AUTOSAR XML (schema 4-2-2)
package /UAES/ASW
  swc implementation Implementation: programming-language=C, sw-version=1.32.1, used-code-generator=Embedded Coder 7.1 (R2018b) 24-May-2018, vendor-id=0, behavior=InternalBehavior
    code-descriptors:
      code Code
        artifact-descriptors:
          short-label=IntLamp_ComCnvRx_c, category=SWSRC
          short-label=IntLamp_ComCnvRx_h, category=SWHDR
          short-label=rtwtypes_h, category=SWHDR
    resource consumption RsrcCons_IntLamp_ComCnvRx
package /UAES/ASW/SwComponentTypes
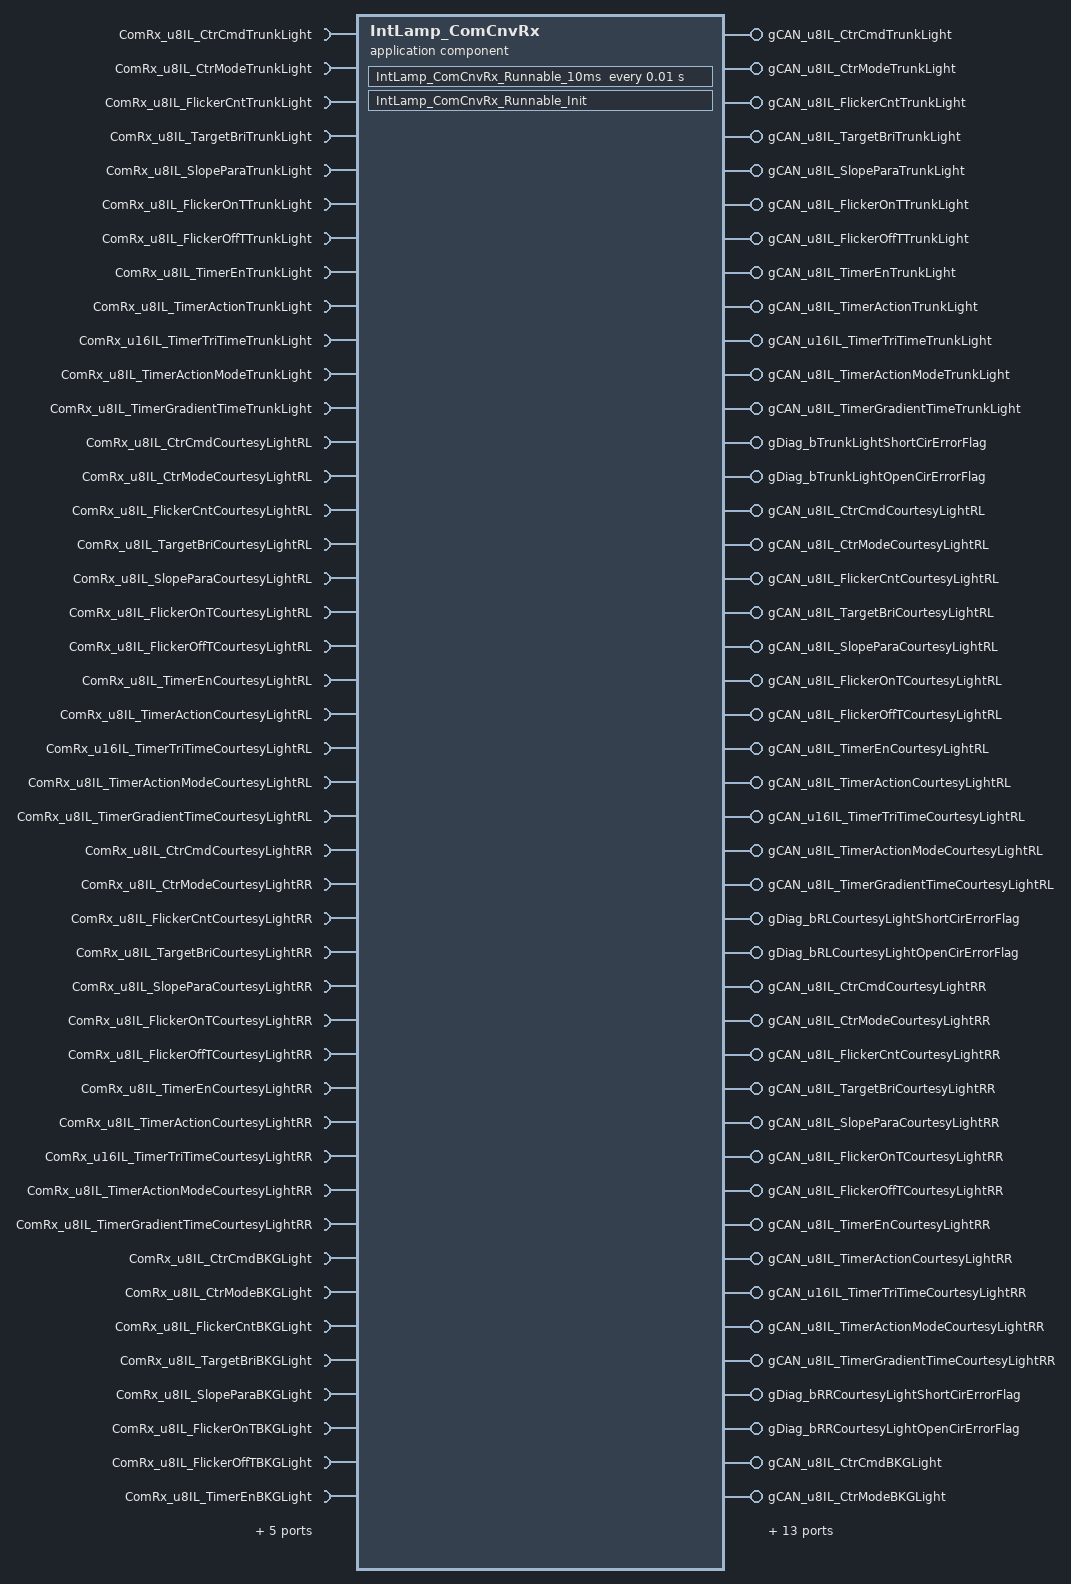
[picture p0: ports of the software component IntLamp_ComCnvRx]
  application sw component type IntLamp_ComCnvRx
    49 x require port:
      ComRx_u8IL_CtrCmdTrunkLight: nonqueued-receiver-com-spec{data-element=ComRx_u8IL_CtrCmdTrunkLight/Val, init-value=0}, required-interface=ComRx_u8IL_CtrCmdTrunkLight
      ComRx_u8IL_CtrModeTrunkLight: nonqueued-receiver-com-spec{data-element=ComRx_u8IL_CtrModeTrunkLight/Val, init-value=0}, required-interface=ComRx_u8IL_CtrModeTrunkLight
      ComRx_u8IL_FlickerCntTrunkLight: nonqueued-receiver-com-spec{data-element=ComRx_u8IL_FlickerCntTrunkLight/Val, init-value=0}, required-interface=ComRx_u8IL_FlickerCntTrunkLight
      ComRx_u8IL_TargetBriTrunkLight: nonqueued-receiver-com-spec{data-element=ComRx_u8IL_TargetBriTrunkLight/Val, init-value=0}, required-interface=ComRx_u8IL_TargetBriTrunkLight
      ComRx_u8IL_SlopeParaTrunkLight: nonqueued-receiver-com-spec{data-element=ComRx_u8IL_SlopeParaTrunkLight/Val, init-value=0}, required-interface=ComRx_u8IL_SlopeParaTrunkLight
      ComRx_u8IL_FlickerOnTTrunkLight: nonqueued-receiver-com-spec{data-element=ComRx_u8IL_FlickerOnTTrunkLight/Val, init-value=0}, required-interface=ComRx_u8IL_FlickerOnTTrunkLight
      ComRx_u8IL_FlickerOffTTrunkLight: nonqueued-receiver-com-spec{data-element=ComRx_u8IL_FlickerOffTTrunkLight/Val, init-value=0}, required-interface=ComRx_u8IL_FlickerOffTTrunkLight
      ComRx_u8IL_TimerEnTrunkLight: nonqueued-receiver-com-spec{data-element=ComRx_u8IL_TimerEnTrunkLight/Val, init-value=0}, required-interface=ComRx_u8IL_TimerEnTrunkLight
      ComRx_u8IL_TimerActionTrunkLight: nonqueued-receiver-com-spec{data-element=ComRx_u8IL_TimerActionTrunkLight/Val, init-value=0}, required-interface=ComRx_u8IL_TimerActionTrunkLight
      ComRx_u16IL_TimerTriTimeTrunkLight: nonqueued-receiver-com-spec{data-element=ComRx_u16IL_TimerTriTimeTrunkLight/Val, init-value=0}, required-interface=ComRx_u16IL_TimerTriTimeTrunkLight
      ComRx_u8IL_TimerActionModeTrunkLight: nonqueued-receiver-com-spec{data-element=ComRx_u8IL_TimerActionModeTrunkLight/Val, init-value=0}, required-interface=ComRx_u8IL_TimerActionModeTrunkLight
      ComRx_u8IL_TimerGradientTimeTrunkLight: nonqueued-receiver-com-spec{data-element=ComRx_u8IL_TimerGradientTimeTrunkLight/Val, init-value=0}, required-interface=ComRx_u8IL_TimerGradientTimeTrunkLight
      ComRx_u8IL_CtrCmdCourtesyLightRL: nonqueued-receiver-com-spec{data-element=ComRx_u8IL_CtrCmdCourtesyLightRL/Val, init-value=0}, required-interface=ComRx_u8IL_CtrCmdCourtesyLightRL
      ComRx_u8IL_CtrModeCourtesyLightRL: nonqueued-receiver-com-spec{data-element=ComRx_u8IL_CtrModeCourtesyLightRL/Val, init-value=0}, required-interface=ComRx_u8IL_CtrModeCourtesyLightRL
      ComRx_u8IL_FlickerCntCourtesyLightRL: nonqueued-receiver-com-spec{data-element=ComRx_u8IL_FlickerCntCourtesyLightRL/Val, init-value=0}, required-interface=ComRx_u8IL_FlickerCntCourtesyLightRL
      ComRx_u8IL_TargetBriCourtesyLightRL: nonqueued-receiver-com-spec{data-element=ComRx_u8IL_TargetBriCourtesyLightRL/Val, init-value=0}, required-interface=ComRx_u8IL_TargetBriCourtesyLightRL
      ComRx_u8IL_SlopeParaCourtesyLightRL: nonqueued-receiver-com-spec{data-element=ComRx_u8IL_SlopeParaCourtesyLightRL/Val, init-value=0}, required-interface=ComRx_u8IL_SlopeParaCourtesyLightRL
      ComRx_u8IL_FlickerOnTCourtesyLightRL: nonqueued-receiver-com-spec{data-element=ComRx_u8IL_FlickerOnTCourtesyLightRL/Val, init-value=0}, required-interface=ComRx_u8IL_FlickerOnTCourtesyLightRL
      ComRx_u8IL_FlickerOffTCourtesyLightRL: nonqueued-receiver-com-spec{data-element=ComRx_u8IL_FlickerOffTCourtesyLightRL/Val, init-value=0}, required-interface=ComRx_u8IL_FlickerOffTCourtesyLightRL
      ComRx_u8IL_TimerEnCourtesyLightRL: nonqueued-receiver-com-spec{data-element=ComRx_u8IL_TimerEnCourtesyLightRL/Val, init-value=0}, required-interface=ComRx_u8IL_TimerEnCourtesyLightRL
      ComRx_u8IL_TimerActionCourtesyLightRL: nonqueued-receiver-com-spec{data-element=ComRx_u8IL_TimerActionCourtesyLightRL/Val, init-value=0}, required-interface=ComRx_u8IL_TimerActionCourtesyLightRL
      ComRx_u16IL_TimerTriTimeCourtesyLightRL: nonqueued-receiver-com-spec{data-element=ComRx_u16IL_TimerTriTimeCourtesyLightRL/Val, init-value=0}, required-interface=ComRx_u16IL_TimerTriTimeCourtesyLightRL
      ComRx_u8IL_TimerActionModeCourtesyLightRL: nonqueued-receiver-com-spec{data-element=ComRx_u8IL_TimerActionModeCourtesyLightRL/Val, init-value=0}, required-interface=ComRx_u8IL_TimerActionModeCourtesyLightRL
      ComRx_u8IL_TimerGradientTimeCourtesyLightRL: nonqueued-receiver-com-spec{data-element=ComRx_u8IL_TimerGradientTimeCourtesyLightRL/Val, init-value=0}, required-interface=ComRx_u8IL_TimerGradientTimeCourtesyLightRL
      ComRx_u8IL_CtrCmdCourtesyLightRR: nonqueued-receiver-com-spec{data-element=ComRx_u8IL_CtrCmdCourtesyLightRR/Val, init-value=0}, required-interface=ComRx_u8IL_CtrCmdCourtesyLightRR
      ComRx_u8IL_CtrModeCourtesyLightRR: nonqueued-receiver-com-spec{data-element=ComRx_u8IL_CtrModeCourtesyLightRR/Val, init-value=0}, required-interface=ComRx_u8IL_CtrModeCourtesyLightRR
      ComRx_u8IL_FlickerCntCourtesyLightRR: nonqueued-receiver-com-spec{data-element=ComRx_u8IL_FlickerCntCourtesyLightRR/Val, init-value=0}, required-interface=ComRx_u8IL_FlickerCntCourtesyLightRR
      ComRx_u8IL_TargetBriCourtesyLightRR: nonqueued-receiver-com-spec{data-element=ComRx_u8IL_TargetBriCourtesyLightRR/Val, init-value=0}, required-interface=ComRx_u8IL_TargetBriCourtesyLightRR
      ComRx_u8IL_SlopeParaCourtesyLightRR: nonqueued-receiver-com-spec{data-element=ComRx_u8IL_SlopeParaCourtesyLightRR/Val, init-value=0}, required-interface=ComRx_u8IL_SlopeParaCourtesyLightRR
      ComRx_u8IL_FlickerOnTCourtesyLightRR: nonqueued-receiver-com-spec{data-element=ComRx_u8IL_FlickerOnTCourtesyLightRR/Val, init-value=0}, required-interface=ComRx_u8IL_FlickerOnTCourtesyLightRR
      ComRx_u8IL_FlickerOffTCourtesyLightRR: nonqueued-receiver-com-spec{data-element=ComRx_u8IL_FlickerOffTCourtesyLightRR/Val, init-value=0}, required-interface=ComRx_u8IL_FlickerOffTCourtesyLightRR
      ComRx_u8IL_TimerEnCourtesyLightRR: nonqueued-receiver-com-spec{data-element=ComRx_u8IL_TimerEnCourtesyLightRR/Val, init-value=0}, required-interface=ComRx_u8IL_TimerEnCourtesyLightRR
      ComRx_u8IL_TimerActionCourtesyLightRR: nonqueued-receiver-com-spec{data-element=ComRx_u8IL_TimerActionCourtesyLightRR/Val, init-value=0}, required-interface=ComRx_u8IL_TimerActionCourtesyLightRR
      ComRx_u16IL_TimerTriTimeCourtesyLightRR: nonqueued-receiver-com-spec{data-element=ComRx_u16IL_TimerTriTimeCourtesyLightRR/Val, init-value=0}, required-interface=ComRx_u16IL_TimerTriTimeCourtesyLightRR
      ComRx_u8IL_TimerActionModeCourtesyLightRR: nonqueued-receiver-com-spec{data-element=ComRx_u8IL_TimerActionModeCourtesyLightRR/Val, init-value=0}, required-interface=ComRx_u8IL_TimerActionModeCourtesyLightRR
      ComRx_u8IL_TimerGradientTimeCourtesyLightRR: nonqueued-receiver-com-spec{data-element=ComRx_u8IL_TimerGradientTimeCourtesyLightRR/Val, init-value=0}, required-interface=ComRx_u8IL_TimerGradientTimeCourtesyLightRR
      ComRx_u8IL_CtrCmdBKGLight: nonqueued-receiver-com-spec{data-element=ComRx_u8IL_CtrCmdBKGLight/Val, init-value=0}, required-interface=ComRx_u8IL_CtrCmdBKGLight
      ComRx_u8IL_CtrModeBKGLight: nonqueued-receiver-com-spec{data-element=ComRx_u8IL_CtrModeBKGLight/Val, init-value=0}, required-interface=ComRx_u8IL_CtrModeBKGLight
      ComRx_u8IL_FlickerCntBKGLight: nonqueued-receiver-com-spec{data-element=ComRx_u8IL_FlickerCntBKGLight/Val, init-value=0}, required-interface=ComRx_u8IL_FlickerCntBKGLight
      ComRx_u8IL_TargetBriBKGLight: nonqueued-receiver-com-spec{data-element=ComRx_u8IL_TargetBriBKGLight/Val, init-value=0}, required-interface=ComRx_u8IL_TargetBriBKGLight
      ComRx_u8IL_SlopeParaBKGLight: nonqueued-receiver-com-spec{data-element=ComRx_u8IL_SlopeParaBKGLight/Val, init-value=0}, required-interface=ComRx_u8IL_SlopeParaBKGLight
      ComRx_u8IL_FlickerOnTBKGLight: nonqueued-receiver-com-spec{data-element=ComRx_u8IL_FlickerOnTBKGLight/Val, init-value=0}, required-interface=ComRx_u8IL_FlickerOnTBKGLight
      ComRx_u8IL_FlickerOffTBKGLight: nonqueued-receiver-com-spec{data-element=ComRx_u8IL_FlickerOffTBKGLight/Val, init-value=0}, required-interface=ComRx_u8IL_FlickerOffTBKGLight
      ComRx_u8IL_TimerEnBKGLight: nonqueued-receiver-com-spec{data-element=ComRx_u8IL_TimerEnBKGLight/Val, init-value=0}, required-interface=ComRx_u8IL_TimerEnBKGLight
      ComRx_u8IL_TimerActionBKGLight: nonqueued-receiver-com-spec{data-element=ComRx_u8IL_TimerActionBKGLight/Val, init-value=0}, required-interface=ComRx_u8IL_TimerActionBKGLight
      ComRx_u16IL_TimerTriTimeBKGLight: nonqueued-receiver-com-spec{data-element=ComRx_u16IL_TimerTriTimeBKGLight/Val, init-value=0}, required-interface=ComRx_u16IL_TimerTriTimeBKGLight
      ComRx_u8IL_TimerActionModeBKGLight: nonqueued-receiver-com-spec{data-element=ComRx_u8IL_TimerActionModeBKGLight/Val, init-value=0}, required-interface=ComRx_u8IL_TimerActionModeBKGLight
      ComRx_u8IL_TimerGradientTimeBKGLight: nonqueued-receiver-com-spec{data-element=ComRx_u8IL_TimerGradientTimeBKGLight/Val, init-value=0}, required-interface=ComRx_u8IL_TimerGradientTimeBKGLight
      ComRx_bIL_CtrCmdTrunkLight_TiOut: nonqueued-receiver-com-spec{data-element=ComRx_bIL_CtrCmdTrunkLight_TiOut/Val, init-value=0}, required-interface=ComRx_bIL_CtrCmdTrunkLight_TiOut
    57 x provide port:
      gCAN_u8IL_CtrCmdTrunkLight: nonqueued-sender-com-spec{data-element=gCAN_u8IL_CtrCmdTrunkLight/Val, init-value=0}, provided-interface=gCAN_u8IL_CtrCmdTrunkLight
      gCAN_u8IL_CtrModeTrunkLight: nonqueued-sender-com-spec{data-element=gCAN_u8IL_CtrModeTrunkLight/Val, init-value=0}, provided-interface=gCAN_u8IL_CtrModeTrunkLight
      gCAN_u8IL_FlickerCntTrunkLight: nonqueued-sender-com-spec{data-element=gCAN_u8IL_FlickerCntTrunkLight/Val, init-value=0}, provided-interface=gCAN_u8IL_FlickerCntTrunkLight
      gCAN_u8IL_TargetBriTrunkLight: nonqueued-sender-com-spec{data-element=gCAN_u8IL_TargetBriTrunkLight/Val, init-value=0}, provided-interface=gCAN_u8IL_TargetBriTrunkLight
      gCAN_u8IL_SlopeParaTrunkLight: nonqueued-sender-com-spec{data-element=gCAN_u8IL_SlopeParaTrunkLight/Val, init-value=0}, provided-interface=gCAN_u8IL_SlopeParaTrunkLight
      gCAN_u8IL_FlickerOnTTrunkLight: nonqueued-sender-com-spec{data-element=gCAN_u8IL_FlickerOnTTrunkLight/Val, init-value=0}, provided-interface=gCAN_u8IL_FlickerOnTTrunkLight
      gCAN_u8IL_FlickerOffTTrunkLight: nonqueued-sender-com-spec{data-element=gCAN_u8IL_FlickerOffTTrunkLight/Val, init-value=0}, provided-interface=gCAN_u8IL_FlickerOffTTrunkLight
      gCAN_u8IL_TimerEnTrunkLight: nonqueued-sender-com-spec{data-element=gCAN_u8IL_TimerEnTrunkLight/Val, init-value=0}, provided-interface=gCAN_u8IL_TimerEnTrunkLight
      gCAN_u8IL_TimerActionTrunkLight: nonqueued-sender-com-spec{data-element=gCAN_u8IL_TimerActionTrunkLight/Val, init-value=0}, provided-interface=gCAN_u8IL_TimerActionTrunkLight
      gCAN_u16IL_TimerTriTimeTrunkLight: nonqueued-sender-com-spec{data-element=gCAN_u16IL_TimerTriTimeTrunkLight/Val, init-value=0}, provided-interface=gCAN_u16IL_TimerTriTimeTrunkLight
      gCAN_u8IL_TimerActionModeTrunkLight: nonqueued-sender-com-spec{data-element=gCAN_u8IL_TimerActionModeTrunkLight/Val, init-value=0}, provided-interface=gCAN_u8IL_TimerActionModeTrunkLight
      gCAN_u8IL_TimerGradientTimeTrunkLight: nonqueued-sender-com-spec{data-element=gCAN_u8IL_TimerGradientTimeTrunkLight/Val, init-value=0}, provided-interface=gCAN_u8IL_TimerGradientTimeTrunkLight
      gDiag_bTrunkLightShortCirErrorFlag: nonqueued-sender-com-spec{data-element=gDiag_bTrunkLightShortCirErrorFlag/Val, init-value=0}, provided-interface=gDiag_bTrunkLightShortCirErrorFlag
      gDiag_bTrunkLightOpenCirErrorFlag: nonqueued-sender-com-spec{data-element=gDiag_bTrunkLightOpenCirErrorFlag/Val, init-value=0}, provided-interface=gDiag_bTrunkLightOpenCirErrorFlag
      gCAN_u8IL_CtrCmdCourtesyLightRL: nonqueued-sender-com-spec{data-element=gCAN_u8IL_CtrCmdCourtesyLightRL/Val, init-value=0}, provided-interface=gCAN_u8IL_CtrCmdCourtesyLightRL
      gCAN_u8IL_CtrModeCourtesyLightRL: nonqueued-sender-com-spec{data-element=gCAN_u8IL_CtrModeCourtesyLightRL/Val, init-value=0}, provided-interface=gCAN_u8IL_CtrModeCourtesyLightRL
      gCAN_u8IL_FlickerCntCourtesyLightRL: nonqueued-sender-com-spec{data-element=gCAN_u8IL_FlickerCntCourtesyLightRL/Val, init-value=0}, provided-interface=gCAN_u8IL_FlickerCntCourtesyLightRL
      gCAN_u8IL_TargetBriCourtesyLightRL: nonqueued-sender-com-spec{data-element=gCAN_u8IL_TargetBriCourtesyLightRL/Val, init-value=0}, provided-interface=gCAN_u8IL_TargetBriCourtesyLightRL
      gCAN_u8IL_SlopeParaCourtesyLightRL: nonqueued-sender-com-spec{data-element=gCAN_u8IL_SlopeParaCourtesyLightRL/Val, init-value=0}, provided-interface=gCAN_u8IL_SlopeParaCourtesyLightRL
      gCAN_u8IL_FlickerOnTCourtesyLightRL: nonqueued-sender-com-spec{data-element=gCAN_u8IL_FlickerOnTCourtesyLightRL/Val, init-value=0}, provided-interface=gCAN_u8IL_FlickerOnTCourtesyLightRL
      gCAN_u8IL_FlickerOffTCourtesyLightRL: nonqueued-sender-com-spec{data-element=gCAN_u8IL_FlickerOffTCourtesyLightRL/Val, init-value=0}, provided-interface=gCAN_u8IL_FlickerOffTCourtesyLightRL
      gCAN_u8IL_TimerEnCourtesyLightRL: nonqueued-sender-com-spec{data-element=gCAN_u8IL_TimerEnCourtesyLightRL/Val, init-value=0}, provided-interface=gCAN_u8IL_TimerEnCourtesyLightRL
      gCAN_u8IL_TimerActionCourtesyLightRL: nonqueued-sender-com-spec{data-element=gCAN_u8IL_TimerActionCourtesyLightRL/Val, init-value=0}, provided-interface=gCAN_u8IL_TimerActionCourtesyLightRL
      gCAN_u16IL_TimerTriTimeCourtesyLightRL: nonqueued-sender-com-spec{data-element=gCAN_u16IL_TimerTriTimeCourtesyLightRL/Val, init-value=0}, provided-interface=gCAN_u16IL_TimerTriTimeCourtesyLightRL
      gCAN_u8IL_TimerActionModeCourtesyLightRL: nonqueued-sender-com-spec{data-element=gCAN_u8IL_TimerActionModeCourtesyLightRL/Val, init-value=0}, provided-interface=gCAN_u8IL_TimerActionModeCourtesyLightRL
      gCAN_u8IL_TimerGradientTimeCourtesyLightRL: nonqueued-sender-com-spec{data-element=gCAN_u8IL_TimerGradientTimeCourtesyLightRL/Val, init-value=0}, provided-interface=gCAN_u8IL_TimerGradientTimeCourtesyLightRL
      gDiag_bRLCourtesyLightShortCirErrorFlag: nonqueued-sender-com-spec{data-element=gDiag_bRLCourtesyLightShortCirErrorFlag/Val, init-value=0}, provided-interface=gDiag_bRLCourtesyLightShortCirErrorFlag
      gDiag_bRLCourtesyLightOpenCirErrorFlag: nonqueued-sender-com-spec{data-element=gDiag_bRLCourtesyLightOpenCirErrorFlag/Val, init-value=0}, provided-interface=gDiag_bRLCourtesyLightOpenCirErrorFlag
      gCAN_u8IL_CtrCmdCourtesyLightRR: nonqueued-sender-com-spec{data-element=gCAN_u8IL_CtrCmdCourtesyLightRR/Val, init-value=0}, provided-interface=gCAN_u8IL_CtrCmdCourtesyLightRR
      gCAN_u8IL_CtrModeCourtesyLightRR: nonqueued-sender-com-spec{data-element=gCAN_u8IL_CtrModeCourtesyLightRR/Val, init-value=0}, provided-interface=gCAN_u8IL_CtrModeCourtesyLightRR
      gCAN_u8IL_FlickerCntCourtesyLightRR: nonqueued-sender-com-spec{data-element=gCAN_u8IL_FlickerCntCourtesyLightRR/Val, init-value=0}, provided-interface=gCAN_u8IL_FlickerCntCourtesyLightRR
      gCAN_u8IL_TargetBriCourtesyLightRR: nonqueued-sender-com-spec{data-element=gCAN_u8IL_TargetBriCourtesyLightRR/Val, init-value=0}, provided-interface=gCAN_u8IL_TargetBriCourtesyLightRR
      gCAN_u8IL_SlopeParaCourtesyLightRR: nonqueued-sender-com-spec{data-element=gCAN_u8IL_SlopeParaCourtesyLightRR/Val, init-value=0}, provided-interface=gCAN_u8IL_SlopeParaCourtesyLightRR
      gCAN_u8IL_FlickerOnTCourtesyLightRR: nonqueued-sender-com-spec{data-element=gCAN_u8IL_FlickerOnTCourtesyLightRR/Val, init-value=0}, provided-interface=gCAN_u8IL_FlickerOnTCourtesyLightRR
      gCAN_u8IL_FlickerOffTCourtesyLightRR: nonqueued-sender-com-spec{data-element=gCAN_u8IL_FlickerOffTCourtesyLightRR/Val, init-value=0}, provided-interface=gCAN_u8IL_FlickerOffTCourtesyLightRR
      gCAN_u8IL_TimerEnCourtesyLightRR: nonqueued-sender-com-spec{data-element=gCAN_u8IL_TimerEnCourtesyLightRR/Val, init-value=0}, provided-interface=gCAN_u8IL_TimerEnCourtesyLightRR
      gCAN_u8IL_TimerActionCourtesyLightRR: nonqueued-sender-com-spec{data-element=gCAN_u8IL_TimerActionCourtesyLightRR/Val, init-value=0}, provided-interface=gCAN_u8IL_TimerActionCourtesyLightRR
      gCAN_u16IL_TimerTriTimeCourtesyLightRR: nonqueued-sender-com-spec{data-element=gCAN_u16IL_TimerTriTimeCourtesyLightRR/Val, init-value=0}, provided-interface=gCAN_u16IL_TimerTriTimeCourtesyLightRR
      gCAN_u8IL_TimerActionModeCourtesyLightRR: nonqueued-sender-com-spec{data-element=gCAN_u8IL_TimerActionModeCourtesyLightRR/Val, init-value=0}, provided-interface=gCAN_u8IL_TimerActionModeCourtesyLightRR
      gCAN_u8IL_TimerGradientTimeCourtesyLightRR: nonqueued-sender-com-spec{data-element=gCAN_u8IL_TimerGradientTimeCourtesyLightRR/Val, init-value=0}, provided-interface=gCAN_u8IL_TimerGradientTimeCourtesyLightRR
      gDiag_bRRCourtesyLightShortCirErrorFlag: nonqueued-sender-com-spec{data-element=gDiag_bRRCourtesyLightShortCirErrorFlag/Val, init-value=0}, provided-interface=gDiag_bRRCourtesyLightShortCirErrorFlag
      gDiag_bRRCourtesyLightOpenCirErrorFlag: nonqueued-sender-com-spec{data-element=gDiag_bRRCourtesyLightOpenCirErrorFlag/Val, init-value=0}, provided-interface=gDiag_bRRCourtesyLightOpenCirErrorFlag
      gCAN_u8IL_CtrCmdBKGLight: nonqueued-sender-com-spec{data-element=gCAN_u8IL_CtrCmdBKGLight/Val, init-value=0}, provided-interface=gCAN_u8IL_CtrCmdBKGLight
      gCAN_u8IL_CtrModeBKGLight: nonqueued-sender-com-spec{data-element=gCAN_u8IL_CtrModeBKGLight/Val, init-value=0}, provided-interface=gCAN_u8IL_CtrModeBKGLight
      gCAN_u8IL_FlickerCntBKGLight: nonqueued-sender-com-spec{data-element=gCAN_u8IL_FlickerCntBKGLight/Val, init-value=0}, provided-interface=gCAN_u8IL_FlickerCntBKGLight
      gCAN_u8IL_TargetBriBKGLight: nonqueued-sender-com-spec{data-element=gCAN_u8IL_TargetBriBKGLight/Val, init-value=0}, provided-interface=gCAN_u8IL_TargetBriBKGLight
      gCAN_u8IL_SlopeParaBKGLight: nonqueued-sender-com-spec{data-element=gCAN_u8IL_SlopeParaBKGLight/Val, init-value=0}, provided-interface=gCAN_u8IL_SlopeParaBKGLight
      gCAN_u8IL_FlickerOnTBKGLight: nonqueued-sender-com-spec{data-element=gCAN_u8IL_FlickerOnTBKGLight/Val, init-value=0}, provided-interface=gCAN_u8IL_FlickerOnTBKGLight
      gCAN_u8IL_FlickerOffTBKGLight: nonqueued-sender-com-spec{data-element=gCAN_u8IL_FlickerOffTBKGLight/Val, init-value=0}, provided-interface=gCAN_u8IL_FlickerOffTBKGLight
      gCAN_u8IL_TimerEnBKGLight: nonqueued-sender-com-spec{data-element=gCAN_u8IL_TimerEnBKGLight/Val, init-value=0}, provided-interface=gCAN_u8IL_TimerEnBKGLight
      gCAN_u8IL_TimerActionBKGLight: nonqueued-sender-com-spec{data-element=gCAN_u8IL_TimerActionBKGLight/Val, init-value=0}, provided-interface=gCAN_u8IL_TimerActionBKGLight
      gCAN_u16IL_TimerTriTimeBKGLight: nonqueued-sender-com-spec{data-element=gCAN_u16IL_TimerTriTimeBKGLight/Val, init-value=0}, provided-interface=gCAN_u16IL_TimerTriTimeBKGLight
      gCAN_u8IL_TimerActionModeBKGLight: nonqueued-sender-com-spec{data-element=gCAN_u8IL_TimerActionModeBKGLight/Val, init-value=0}, provided-interface=gCAN_u8IL_TimerActionModeBKGLight
      gCAN_u8IL_TimerGradientTimeBKGLight: nonqueued-sender-com-spec{data-element=gCAN_u8IL_TimerGradientTimeBKGLight/Val, init-value=0}, provided-interface=gCAN_u8IL_TimerGradientTimeBKGLight
      gDiag_bReBkgLightPowerShortCirErrorFlag: nonqueued-sender-com-spec{data-element=gDiag_bReBkgLightPowerShortCirErrorFlag/Val, init-value=0}, provided-interface=gDiag_bReBkgLightPowerShortCirErrorFlag
      gDiag_bReBkgLightPowerOpenCirErrorFlag: nonqueued-sender-com-spec{data-element=gDiag_bReBkgLightPowerOpenCirErrorFlag/Val, init-value=0}, provided-interface=gDiag_bReBkgLightPowerOpenCirErrorFlag
      gASI_bIL_CtrCmdTrunkLight_TimeOut: nonqueued-sender-com-spec{data-element=gASI_bIL_CtrCmdTrunkLight_TimeOut/Val, init-value=0}, provided-interface=gASI_bIL_CtrCmdTrunkLight_TimeOut
    behavior InternalBehavior: handle-termination-and-restart=NO-SUPPORT
      init event IntLamp_ComCnvRx_InitEvent: start-on-event=IntLamp_ComCnvRx_Runnable_Init
      timing event TMT_IntLamp_ComCnvRx_Runnable_10ms: start-on-event=IntLamp_ComCnvRx_Runnable_10ms, period=0.01
      runnable IntLamp_ComCnvRx_Runnable_Init
      runnable IntLamp_ComCnvRx_Runnable_10ms
        data-receive-point-by-arguments:
          49 x access:
            IN_ComRx_bIL_CtrCmdTrunkLight_TiOut_Val: accessed-variable=ComRx_bIL_CtrCmdTrunkLight_TiOut.Val
            IN_ComRx_u16IL_TimerTriTimeBKGLight_Val: accessed-variable=ComRx_u16IL_TimerTriTimeBKGLight.Val
            IN_ComRx_u16IL_TimerTriTimeCourtesyLightRL_Val: accessed-variable=ComRx_u16IL_TimerTriTimeCourtesyLightRL.Val
            IN_ComRx_u16IL_TimerTriTimeCourtesyLightRR_Val: accessed-variable=ComRx_u16IL_TimerTriTimeCourtesyLightRR.Val
            IN_ComRx_u16IL_TimerTriTimeTrunkLight_Val: accessed-variable=ComRx_u16IL_TimerTriTimeTrunkLight.Val
            IN_ComRx_u8IL_CtrCmdBKGLight_Val: accessed-variable=ComRx_u8IL_CtrCmdBKGLight.Val
            IN_ComRx_u8IL_CtrCmdCourtesyLightRL_Val: accessed-variable=ComRx_u8IL_CtrCmdCourtesyLightRL.Val
            IN_ComRx_u8IL_CtrCmdCourtesyLightRR_Val: accessed-variable=ComRx_u8IL_CtrCmdCourtesyLightRR.Val
            IN_ComRx_u8IL_CtrCmdTrunkLight_Val: accessed-variable=ComRx_u8IL_CtrCmdTrunkLight.Val
            IN_ComRx_u8IL_CtrModeBKGLight_Val: accessed-variable=ComRx_u8IL_CtrModeBKGLight.Val
            IN_ComRx_u8IL_CtrModeCourtesyLightRL_Val: accessed-variable=ComRx_u8IL_CtrModeCourtesyLightRL.Val
            IN_ComRx_u8IL_CtrModeCourtesyLightRR_Val: accessed-variable=ComRx_u8IL_CtrModeCourtesyLightRR.Val
            IN_ComRx_u8IL_CtrModeTrunkLight_Val: accessed-variable=ComRx_u8IL_CtrModeTrunkLight.Val
            IN_ComRx_u8IL_FlickerCntBKGLight_Val: accessed-variable=ComRx_u8IL_FlickerCntBKGLight.Val
            IN_ComRx_u8IL_FlickerCntCourtesyLightRL_Val: accessed-variable=ComRx_u8IL_FlickerCntCourtesyLightRL.Val
            IN_ComRx_u8IL_FlickerCntCourtesyLightRR_Val: accessed-variable=ComRx_u8IL_FlickerCntCourtesyLightRR.Val
            IN_ComRx_u8IL_FlickerCntTrunkLight_Val: accessed-variable=ComRx_u8IL_FlickerCntTrunkLight.Val
            IN_ComRx_u8IL_FlickerOffTBKGLight_Val: accessed-variable=ComRx_u8IL_FlickerOffTBKGLight.Val
            IN_ComRx_u8IL_FlickerOffTCourtesyLightRL_Val: accessed-variable=ComRx_u8IL_FlickerOffTCourtesyLightRL.Val
            IN_ComRx_u8IL_FlickerOffTCourtesyLightRR_Val: accessed-variable=ComRx_u8IL_FlickerOffTCourtesyLightRR.Val
            IN_ComRx_u8IL_FlickerOffTTrunkLight_Val: accessed-variable=ComRx_u8IL_FlickerOffTTrunkLight.Val
            IN_ComRx_u8IL_FlickerOnTBKGLight_Val: accessed-variable=ComRx_u8IL_FlickerOnTBKGLight.Val
            IN_ComRx_u8IL_FlickerOnTCourtesyLightRL_Val: accessed-variable=ComRx_u8IL_FlickerOnTCourtesyLightRL.Val
            IN_ComRx_u8IL_FlickerOnTCourtesyLightRR_Val: accessed-variable=ComRx_u8IL_FlickerOnTCourtesyLightRR.Val
            IN_ComRx_u8IL_FlickerOnTTrunkLight_Val: accessed-variable=ComRx_u8IL_FlickerOnTTrunkLight.Val
            IN_ComRx_u8IL_SlopeParaBKGLight_Val: accessed-variable=ComRx_u8IL_SlopeParaBKGLight.Val
            IN_ComRx_u8IL_SlopeParaCourtesyLightRL_Val: accessed-variable=ComRx_u8IL_SlopeParaCourtesyLightRL.Val
            IN_ComRx_u8IL_SlopeParaCourtesyLightRR_Val: accessed-variable=ComRx_u8IL_SlopeParaCourtesyLightRR.Val
            IN_ComRx_u8IL_SlopeParaTrunkLight_Val: accessed-variable=ComRx_u8IL_SlopeParaTrunkLight.Val
            IN_ComRx_u8IL_TargetBriBKGLight_Val: accessed-variable=ComRx_u8IL_TargetBriBKGLight.Val
            IN_ComRx_u8IL_TargetBriCourtesyLightRL_Val: accessed-variable=ComRx_u8IL_TargetBriCourtesyLightRL.Val
            IN_ComRx_u8IL_TargetBriCourtesyLightRR_Val: accessed-variable=ComRx_u8IL_TargetBriCourtesyLightRR.Val
            IN_ComRx_u8IL_TargetBriTrunkLight_Val: accessed-variable=ComRx_u8IL_TargetBriTrunkLight.Val
            IN_ComRx_u8IL_TimerActionBKGLight_Val: accessed-variable=ComRx_u8IL_TimerActionBKGLight.Val
            IN_ComRx_u8IL_TimerActionCourtesyLightRL_Val: accessed-variable=ComRx_u8IL_TimerActionCourtesyLightRL.Val
            IN_ComRx_u8IL_TimerActionCourtesyLightRR_Val: accessed-variable=ComRx_u8IL_TimerActionCourtesyLightRR.Val
            IN_ComRx_u8IL_TimerActionModeBKGLight_Val: accessed-variable=ComRx_u8IL_TimerActionModeBKGLight.Val
            IN_ComRx_u8IL_TimerActionModeCourtesyLightRL_Val: accessed-variable=ComRx_u8IL_TimerActionModeCourtesyLightRL.Val
            IN_ComRx_u8IL_TimerActionModeCourtesyLightRR_Val: accessed-variable=ComRx_u8IL_TimerActionModeCourtesyLightRR.Val
            IN_ComRx_u8IL_TimerActionModeTrunkLight_Val: accessed-variable=ComRx_u8IL_TimerActionModeTrunkLight.Val
            IN_ComRx_u8IL_TimerActionTrunkLight_Val: accessed-variable=ComRx_u8IL_TimerActionTrunkLight.Val
            IN_ComRx_u8IL_TimerEnBKGLight_Val: accessed-variable=ComRx_u8IL_TimerEnBKGLight.Val
            IN_ComRx_u8IL_TimerEnCourtesyLightRL_Val: accessed-variable=ComRx_u8IL_TimerEnCourtesyLightRL.Val
            IN_ComRx_u8IL_TimerEnCourtesyLightRR_Val: accessed-variable=ComRx_u8IL_TimerEnCourtesyLightRR.Val
            IN_ComRx_u8IL_TimerEnTrunkLight_Val: accessed-variable=ComRx_u8IL_TimerEnTrunkLight.Val
            IN_ComRx_u8IL_TimerGradientTimeBKGLight_Val: accessed-variable=ComRx_u8IL_TimerGradientTimeBKGLight.Val
            IN_ComRx_u8IL_TimerGradientTimeCourtesyLightRL_Val: accessed-variable=ComRx_u8IL_TimerGradientTimeCourtesyLightRL.Val
            IN_ComRx_u8IL_TimerGradientTimeCourtesyLightRR_Val: accessed-variable=ComRx_u8IL_TimerGradientTimeCourtesyLightRR.Val
            IN_ComRx_u8IL_TimerGradientTimeTrunkLight_Val: accessed-variable=ComRx_u8IL_TimerGradientTimeTrunkLight.Val
        data-send-points:
          57 x access:
            OUT_gCAN_u8IL_CtrCmdTrunkLight_Val: accessed-variable=gCAN_u8IL_CtrCmdTrunkLight.Val
            OUT_gCAN_u8IL_CtrModeTrunkLight_Val: accessed-variable=gCAN_u8IL_CtrModeTrunkLight.Val
            OUT_gCAN_u8IL_FlickerCntTrunkLight_Val: accessed-variable=gCAN_u8IL_FlickerCntTrunkLight.Val
            OUT_gCAN_u8IL_TargetBriTrunkLight_Val: accessed-variable=gCAN_u8IL_TargetBriTrunkLight.Val
            OUT_gCAN_u8IL_SlopeParaTrunkLight_Val: accessed-variable=gCAN_u8IL_SlopeParaTrunkLight.Val
            OUT_gCAN_u8IL_FlickerOnTTrunkLight_Val: accessed-variable=gCAN_u8IL_FlickerOnTTrunkLight.Val
            OUT_gCAN_u8IL_FlickerOffTTrunkLight_Val: accessed-variable=gCAN_u8IL_FlickerOffTTrunkLight.Val
            OUT_gCAN_u8IL_TimerEnTrunkLight_Val: accessed-variable=gCAN_u8IL_TimerEnTrunkLight.Val
            OUT_gCAN_u8IL_TimerActionTrunkLight_Val: accessed-variable=gCAN_u8IL_TimerActionTrunkLight.Val
            OUT_gCAN_u16IL_TimerTriTimeTrunkLight_Val: accessed-variable=gCAN_u16IL_TimerTriTimeTrunkLight.Val
            OUT_gCAN_u8IL_TimerActionModeTrunkLight_Val: accessed-variable=gCAN_u8IL_TimerActionModeTrunkLight.Val
            OUT_gCAN_u8IL_TimerGradientTimeTrunkLight_Val: accessed-variable=gCAN_u8IL_TimerGradientTimeTrunkLight.Val
            OUT_gDiag_bTrunkLightShortCirErrorFlag_Val: accessed-variable=gDiag_bTrunkLightShortCirErrorFlag.Val
            OUT_gDiag_bTrunkLightOpenCirErrorFlag_Val: accessed-variable=gDiag_bTrunkLightOpenCirErrorFlag.Val
            OUT_gCAN_u8IL_CtrCmdCourtesyLightRL_Val: accessed-variable=gCAN_u8IL_CtrCmdCourtesyLightRL.Val
            OUT_gCAN_u8IL_CtrModeCourtesyLightRL_Val: accessed-variable=gCAN_u8IL_CtrModeCourtesyLightRL.Val
            OUT_gCAN_u8IL_FlickerCntCourtesyLightRL_Val: accessed-variable=gCAN_u8IL_FlickerCntCourtesyLightRL.Val
            OUT_gCAN_u8IL_TargetBriCourtesyLightRL_Val: accessed-variable=gCAN_u8IL_TargetBriCourtesyLightRL.Val
            OUT_gCAN_u8IL_SlopeParaCourtesyLightRL_Val: accessed-variable=gCAN_u8IL_SlopeParaCourtesyLightRL.Val
            OUT_gCAN_u8IL_FlickerOnTCourtesyLightRL_Val: accessed-variable=gCAN_u8IL_FlickerOnTCourtesyLightRL.Val
            OUT_gCAN_u8IL_FlickerOffTCourtesyLightRL_Val: accessed-variable=gCAN_u8IL_FlickerOffTCourtesyLightRL.Val
            OUT_gCAN_u8IL_TimerEnCourtesyLightRL_Val: accessed-variable=gCAN_u8IL_TimerEnCourtesyLightRL.Val
            OUT_gCAN_u8IL_TimerActionCourtesyLightRL_Val: accessed-variable=gCAN_u8IL_TimerActionCourtesyLightRL.Val
            OUT_gCAN_u16IL_TimerTriTimeCourtesyLightRL_Val: accessed-variable=gCAN_u16IL_TimerTriTimeCourtesyLightRL.Val
            OUT_gCAN_u8IL_TimerActionModeCourtesyLightRL_Val: accessed-variable=gCAN_u8IL_TimerActionModeCourtesyLightRL.Val
            OUT_gCAN_u8IL_TimerGradientTimeCourtesyLightRL_Val: accessed-variable=gCAN_u8IL_TimerGradientTimeCourtesyLightRL.Val
            OUT_gDiag_bRLCourtesyLightShortCirErrorFlag_Val: accessed-variable=gDiag_bRLCourtesyLightShortCirErrorFlag.Val
            OUT_gDiag_bRLCourtesyLightOpenCirErrorFlag_Val: accessed-variable=gDiag_bRLCourtesyLightOpenCirErrorFlag.Val
            OUT_gCAN_u8IL_CtrCmdCourtesyLightRR_Val: accessed-variable=gCAN_u8IL_CtrCmdCourtesyLightRR.Val
            OUT_gCAN_u8IL_CtrModeCourtesyLightRR_Val: accessed-variable=gCAN_u8IL_CtrModeCourtesyLightRR.Val
            OUT_gCAN_u8IL_FlickerCntCourtesyLightRR_Val: accessed-variable=gCAN_u8IL_FlickerCntCourtesyLightRR.Val
            OUT_gCAN_u8IL_TargetBriCourtesyLightRR_Val: accessed-variable=gCAN_u8IL_TargetBriCourtesyLightRR.Val
            OUT_gCAN_u8IL_SlopeParaCourtesyLightRR_Val: accessed-variable=gCAN_u8IL_SlopeParaCourtesyLightRR.Val
            OUT_gCAN_u8IL_FlickerOnTCourtesyLightRR_Val: accessed-variable=gCAN_u8IL_FlickerOnTCourtesyLightRR.Val
            OUT_gCAN_u8IL_FlickerOffTCourtesyLightRR_Val: accessed-variable=gCAN_u8IL_FlickerOffTCourtesyLightRR.Val
            OUT_gCAN_u8IL_TimerEnCourtesyLightRR_Val: accessed-variable=gCAN_u8IL_TimerEnCourtesyLightRR.Val
            OUT_gCAN_u8IL_TimerActionCourtesyLightRR_Val: accessed-variable=gCAN_u8IL_TimerActionCourtesyLightRR.Val
            OUT_gCAN_u16IL_TimerTriTimeCourtesyLightRR_Val: accessed-variable=gCAN_u16IL_TimerTriTimeCourtesyLightRR.Val
            OUT_gCAN_u8IL_TimerActionModeCourtesyLightRR_Val: accessed-variable=gCAN_u8IL_TimerActionModeCourtesyLightRR.Val
            OUT_gCAN_u8IL_TimerGradientTimeCourtesyLightRR_Val: accessed-variable=gCAN_u8IL_TimerGradientTimeCourtesyLightRR.Val
            OUT_gDiag_bRRCourtesyLightShortCirErrorFlag_Val: accessed-variable=gDiag_bRRCourtesyLightShortCirErrorFlag.Val
            OUT_gDiag_bRRCourtesyLightOpenCirErrorFlag_Val: accessed-variable=gDiag_bRRCourtesyLightOpenCirErrorFlag.Val
            OUT_gCAN_u8IL_CtrCmdBKGLight_Val: accessed-variable=gCAN_u8IL_CtrCmdBKGLight.Val
            OUT_gCAN_u8IL_CtrModeBKGLight_Val: accessed-variable=gCAN_u8IL_CtrModeBKGLight.Val
            OUT_gCAN_u8IL_FlickerCntBKGLight_Val: accessed-variable=gCAN_u8IL_FlickerCntBKGLight.Val
            OUT_gCAN_u8IL_TargetBriBKGLight_Val: accessed-variable=gCAN_u8IL_TargetBriBKGLight.Val
            OUT_gCAN_u8IL_SlopeParaBKGLight_Val: accessed-variable=gCAN_u8IL_SlopeParaBKGLight.Val
            OUT_gCAN_u8IL_FlickerOnTBKGLight_Val: accessed-variable=gCAN_u8IL_FlickerOnTBKGLight.Val
            OUT_gCAN_u8IL_FlickerOffTBKGLight_Val: accessed-variable=gCAN_u8IL_FlickerOffTBKGLight.Val
            OUT_gCAN_u8IL_TimerEnBKGLight_Val: accessed-variable=gCAN_u8IL_TimerEnBKGLight.Val
            OUT_gCAN_u8IL_TimerActionBKGLight_Val: accessed-variable=gCAN_u8IL_TimerActionBKGLight.Val
            OUT_gCAN_u16IL_TimerTriTimeBKGLight_Val: accessed-variable=gCAN_u16IL_TimerTriTimeBKGLight.Val
            OUT_gCAN_u8IL_TimerActionModeBKGLight_Val: accessed-variable=gCAN_u8IL_TimerActionModeBKGLight.Val
            OUT_gCAN_u8IL_TimerGradientTimeBKGLight_Val: accessed-variable=gCAN_u8IL_TimerGradientTimeBKGLight.Val
            OUT_gDiag_bReBkgLightPowerShortCirErrorFlag_Val: accessed-variable=gDiag_bReBkgLightPowerShortCirErrorFlag.Val
            OUT_gDiag_bReBkgLightPowerOpenCirErrorFlag_Val: accessed-variable=gDiag_bReBkgLightPowerOpenCirErrorFlag.Val
            OUT_gASI_bIL_CtrCmdTrunkLight_TimeOut_Val: accessed-variable=gASI_bIL_CtrCmdTrunkLight_TimeOut.Val
package /UAES/ASW/PortInterfaces
  106 x sender receiver interface:
    ComRx_u8IL_CtrCmdTrunkLight
      data Val: category=VALUE, sw-calibration-access=READ-ONLY, type=uint8
    ComRx_u8IL_CtrModeTrunkLight
      data Val: category=VALUE, sw-calibration-access=READ-ONLY, type=uint8
    ComRx_u8IL_FlickerCntTrunkLight
      data Val: category=VALUE, sw-calibration-access=READ-ONLY, type=uint8
    ComRx_u8IL_TargetBriTrunkLight
      data Val: category=VALUE, sw-calibration-access=READ-ONLY, type=uint8
    ComRx_u8IL_SlopeParaTrunkLight
      data Val: category=VALUE, sw-calibration-access=READ-ONLY, type=uint8
    ComRx_u8IL_FlickerOnTTrunkLight
      data Val: category=VALUE, sw-calibration-access=READ-ONLY, type=uint8
    ComRx_u8IL_FlickerOffTTrunkLight
      data Val: category=VALUE, sw-calibration-access=READ-ONLY, type=uint8
    ComRx_u8IL_TimerEnTrunkLight
      data Val: category=VALUE, sw-calibration-access=READ-ONLY, type=uint8
    ComRx_u8IL_TimerActionTrunkLight
      data Val: category=VALUE, sw-calibration-access=READ-ONLY, type=uint8
    ComRx_u16IL_TimerTriTimeTrunkLight
      data Val: category=VALUE, sw-calibration-access=READ-ONLY, type=uint16
    ComRx_u8IL_TimerActionModeTrunkLight
      data Val: category=VALUE, sw-calibration-access=READ-ONLY, type=uint8
    ComRx_u8IL_TimerGradientTimeTrunkLight
      data Val: category=VALUE, sw-calibration-access=READ-ONLY, type=uint8
    ComRx_u8IL_CtrCmdCourtesyLightRL
      data Val: category=VALUE, sw-calibration-access=READ-ONLY, type=uint8
    ComRx_u8IL_CtrModeCourtesyLightRL
      data Val: category=VALUE, sw-calibration-access=READ-ONLY, type=uint8
    ComRx_u8IL_FlickerCntCourtesyLightRL
      data Val: category=VALUE, sw-calibration-access=READ-ONLY, type=uint8
    ComRx_u8IL_TargetBriCourtesyLightRL
      data Val: category=VALUE, sw-calibration-access=READ-ONLY, type=uint8
    ComRx_u8IL_SlopeParaCourtesyLightRL
      data Val: category=VALUE, sw-calibration-access=READ-ONLY, type=uint8
    ComRx_u8IL_FlickerOnTCourtesyLightRL
      data Val: category=VALUE, sw-calibration-access=READ-ONLY, type=uint8
    ComRx_u8IL_FlickerOffTCourtesyLightRL
      data Val: category=VALUE, sw-calibration-access=READ-ONLY, type=uint8
    ComRx_u8IL_TimerEnCourtesyLightRL
      data Val: category=VALUE, sw-calibration-access=READ-ONLY, type=uint8
    ComRx_u8IL_TimerActionCourtesyLightRL
      data Val: category=VALUE, sw-calibration-access=READ-ONLY, type=uint8
    ComRx_u16IL_TimerTriTimeCourtesyLightRL
      data Val: category=VALUE, sw-calibration-access=READ-ONLY, type=uint16
    ComRx_u8IL_TimerActionModeCourtesyLightRL
      data Val: category=VALUE, sw-calibration-access=READ-ONLY, type=uint8
    ComRx_u8IL_TimerGradientTimeCourtesyLightRL
      data Val: category=VALUE, sw-calibration-access=READ-ONLY, type=uint8
    ComRx_u8IL_CtrCmdCourtesyLightRR
      data Val: category=VALUE, sw-calibration-access=READ-ONLY, type=uint8
    ComRx_u8IL_CtrModeCourtesyLightRR
      data Val: category=VALUE, sw-calibration-access=READ-ONLY, type=uint8
    ComRx_u8IL_FlickerCntCourtesyLightRR
      data Val: category=VALUE, sw-calibration-access=READ-ONLY, type=uint8
    ComRx_u8IL_TargetBriCourtesyLightRR
      data Val: category=VALUE, sw-calibration-access=READ-ONLY, type=uint8
    ComRx_u8IL_SlopeParaCourtesyLightRR
      data Val: category=VALUE, sw-calibration-access=READ-ONLY, type=uint8
    ComRx_u8IL_FlickerOnTCourtesyLightRR
      data Val: category=VALUE, sw-calibration-access=READ-ONLY, type=uint8
    ComRx_u8IL_FlickerOffTCourtesyLightRR
      data Val: category=VALUE, sw-calibration-access=READ-ONLY, type=uint8
    ComRx_u8IL_TimerEnCourtesyLightRR
      data Val: category=VALUE, sw-calibration-access=READ-ONLY, type=uint8
    ComRx_u8IL_TimerActionCourtesyLightRR
      data Val: category=VALUE, sw-calibration-access=READ-ONLY, type=uint8
    ComRx_u16IL_TimerTriTimeCourtesyLightRR
      data Val: category=VALUE, sw-calibration-access=READ-ONLY, type=uint16
    ComRx_u8IL_TimerActionModeCourtesyLightRR
      data Val: category=VALUE, sw-calibration-access=READ-ONLY, type=uint8
    ComRx_u8IL_TimerGradientTimeCourtesyLightRR
      data Val: category=VALUE, sw-calibration-access=READ-ONLY, type=uint8
    ComRx_u8IL_CtrCmdBKGLight
      data Val: category=VALUE, sw-calibration-access=READ-ONLY, type=uint8
    ComRx_u8IL_CtrModeBKGLight
      data Val: category=VALUE, sw-calibration-access=READ-ONLY, type=uint8
    ComRx_u8IL_FlickerCntBKGLight
      data Val: category=VALUE, sw-calibration-access=READ-ONLY, type=uint8
    ComRx_u8IL_TargetBriBKGLight
      data Val: category=VALUE, sw-calibration-access=READ-ONLY, type=uint8
    ComRx_u8IL_SlopeParaBKGLight
      data Val: category=VALUE, sw-calibration-access=READ-ONLY, type=uint8
    ComRx_u8IL_FlickerOnTBKGLight
      data Val: category=VALUE, sw-calibration-access=READ-ONLY, type=uint8
    ComRx_u8IL_FlickerOffTBKGLight
      data Val: category=VALUE, sw-calibration-access=READ-ONLY, type=uint8
    ComRx_u8IL_TimerEnBKGLight
      data Val: category=VALUE, sw-calibration-access=READ-ONLY, type=uint8
    ComRx_u8IL_TimerActionBKGLight
      data Val: category=VALUE, sw-calibration-access=READ-ONLY, type=uint8
    ComRx_u16IL_TimerTriTimeBKGLight
      data Val: category=VALUE, sw-calibration-access=READ-ONLY, type=uint16
    ComRx_u8IL_TimerActionModeBKGLight
      data Val: category=VALUE, sw-calibration-access=READ-ONLY, type=uint8
    ComRx_u8IL_TimerGradientTimeBKGLight
      data Val: category=VALUE, sw-calibration-access=READ-ONLY, type=uint8
    ComRx_bIL_CtrCmdTrunkLight_TiOut
      data Val: category=VALUE, sw-calibration-access=READ-ONLY, type=boolean
    gCAN_u8IL_CtrCmdTrunkLight
      data Val: category=VALUE, sw-calibration-access=READ-ONLY, type=uint8
    gCAN_u8IL_CtrModeTrunkLight
      data Val: category=VALUE, sw-calibration-access=READ-ONLY, type=uint8
    gCAN_u8IL_FlickerCntTrunkLight
      data Val: category=VALUE, sw-calibration-access=READ-ONLY, type=uint8
    gCAN_u8IL_TargetBriTrunkLight
      data Val: category=VALUE, sw-calibration-access=READ-ONLY, type=uint8
    gCAN_u8IL_SlopeParaTrunkLight
      data Val: category=VALUE, sw-calibration-access=READ-ONLY, type=uint8
    gCAN_u8IL_FlickerOnTTrunkLight
      data Val: category=VALUE, sw-calibration-access=READ-ONLY, type=uint8
    gCAN_u8IL_FlickerOffTTrunkLight
      data Val: category=VALUE, sw-calibration-access=READ-ONLY, type=uint8
    gCAN_u8IL_TimerEnTrunkLight
      data Val: category=VALUE, sw-calibration-access=READ-ONLY, type=uint8
    gCAN_u8IL_TimerActionTrunkLight
      data Val: category=VALUE, sw-calibration-access=READ-ONLY, type=uint8
    gCAN_u16IL_TimerTriTimeTrunkLight
      data Val: category=VALUE, sw-calibration-access=READ-ONLY, type=uint16
    gCAN_u8IL_TimerActionModeTrunkLight
      data Val: category=VALUE, sw-calibration-access=READ-ONLY, type=uint8
    gCAN_u8IL_TimerGradientTimeTrunkLight
      data Val: category=VALUE, sw-calibration-access=READ-ONLY, type=uint8
    gDiag_bTrunkLightShortCirErrorFlag
      data Val: category=VALUE, sw-calibration-access=READ-ONLY, type=boolean
    gDiag_bTrunkLightOpenCirErrorFlag
      data Val: category=VALUE, sw-calibration-access=READ-ONLY, type=boolean
    gCAN_u8IL_CtrCmdCourtesyLightRL
      data Val: category=VALUE, sw-calibration-access=READ-ONLY, type=uint8
    gCAN_u8IL_CtrModeCourtesyLightRL
      data Val: category=VALUE, sw-calibration-access=READ-ONLY, type=uint8
    gCAN_u8IL_FlickerCntCourtesyLightRL
      data Val: category=VALUE, sw-calibration-access=READ-ONLY, type=uint8
    gCAN_u8IL_TargetBriCourtesyLightRL
      data Val: category=VALUE, sw-calibration-access=READ-ONLY, type=uint8
    gCAN_u8IL_SlopeParaCourtesyLightRL
      data Val: category=VALUE, sw-calibration-access=READ-ONLY, type=uint8
    gCAN_u8IL_FlickerOnTCourtesyLightRL
      data Val: category=VALUE, sw-calibration-access=READ-ONLY, type=uint8
    gCAN_u8IL_FlickerOffTCourtesyLightRL
      data Val: category=VALUE, sw-calibration-access=READ-ONLY, type=uint8
    gCAN_u8IL_TimerEnCourtesyLightRL
      data Val: category=VALUE, sw-calibration-access=READ-ONLY, type=uint8
    gCAN_u8IL_TimerActionCourtesyLightRL
      data Val: category=VALUE, sw-calibration-access=READ-ONLY, type=uint8
    gCAN_u16IL_TimerTriTimeCourtesyLightRL
      data Val: category=VALUE, sw-calibration-access=READ-ONLY, type=uint16
    gCAN_u8IL_TimerActionModeCourtesyLightRL
      data Val: category=VALUE, sw-calibration-access=READ-ONLY, type=uint8
    gCAN_u8IL_TimerGradientTimeCourtesyLightRL
      data Val: category=VALUE, sw-calibration-access=READ-ONLY, type=uint8
    gDiag_bRLCourtesyLightShortCirErrorFlag
      data Val: category=VALUE, sw-calibration-access=READ-ONLY, type=boolean
    gDiag_bRLCourtesyLightOpenCirErrorFlag
      data Val: category=VALUE, sw-calibration-access=READ-ONLY, type=boolean
    gCAN_u8IL_CtrCmdCourtesyLightRR
      data Val: category=VALUE, sw-calibration-access=READ-ONLY, type=uint8
    gCAN_u8IL_CtrModeCourtesyLightRR
      data Val: category=VALUE, sw-calibration-access=READ-ONLY, type=uint8
    gCAN_u8IL_FlickerCntCourtesyLightRR
      data Val: category=VALUE, sw-calibration-access=READ-ONLY, type=uint8
    gCAN_u8IL_TargetBriCourtesyLightRR
      data Val: category=VALUE, sw-calibration-access=READ-ONLY, type=uint8
    gCAN_u8IL_SlopeParaCourtesyLightRR
      data Val: category=VALUE, sw-calibration-access=READ-ONLY, type=uint8
    gCAN_u8IL_FlickerOnTCourtesyLightRR
      data Val: category=VALUE, sw-calibration-access=READ-ONLY, type=uint8
    gCAN_u8IL_FlickerOffTCourtesyLightRR
      data Val: category=VALUE, sw-calibration-access=READ-ONLY, type=uint8
    gCAN_u8IL_TimerEnCourtesyLightRR
      data Val: category=VALUE, sw-calibration-access=READ-ONLY, type=uint8
    gCAN_u8IL_TimerActionCourtesyLightRR
      data Val: category=VALUE, sw-calibration-access=READ-ONLY, type=uint8
    gCAN_u16IL_TimerTriTimeCourtesyLightRR
      data Val: category=VALUE, sw-calibration-access=READ-ONLY, type=uint16
    gCAN_u8IL_TimerActionModeCourtesyLightRR
      data Val: category=VALUE, sw-calibration-access=READ-ONLY, type=uint8
    gCAN_u8IL_TimerGradientTimeCourtesyLightRR
      data Val: category=VALUE, sw-calibration-access=READ-ONLY, type=uint8
    gDiag_bRRCourtesyLightShortCirErrorFlag
      data Val: category=VALUE, sw-calibration-access=READ-ONLY, type=boolean
    gDiag_bRRCourtesyLightOpenCirErrorFlag
      data Val: category=VALUE, sw-calibration-access=READ-ONLY, type=boolean
    gCAN_u8IL_CtrCmdBKGLight
      data Val: category=VALUE, sw-calibration-access=READ-ONLY, type=uint8
    gCAN_u8IL_CtrModeBKGLight
      data Val: category=VALUE, sw-calibration-access=READ-ONLY, type=uint8
    gCAN_u8IL_FlickerCntBKGLight
      data Val: category=VALUE, sw-calibration-access=READ-ONLY, type=uint8
    gCAN_u8IL_TargetBriBKGLight
      data Val: category=VALUE, sw-calibration-access=READ-ONLY, type=uint8
    gCAN_u8IL_SlopeParaBKGLight
      data Val: category=VALUE, sw-calibration-access=READ-ONLY, type=uint8
    gCAN_u8IL_FlickerOnTBKGLight
      data Val: category=VALUE, sw-calibration-access=READ-ONLY, type=uint8
    gCAN_u8IL_FlickerOffTBKGLight
      data Val: category=VALUE, sw-calibration-access=READ-ONLY, type=uint8
    gCAN_u8IL_TimerEnBKGLight
      data Val: category=VALUE, sw-calibration-access=READ-ONLY, type=uint8
    gCAN_u8IL_TimerActionBKGLight
      data Val: category=VALUE, sw-calibration-access=READ-ONLY, type=uint8
    gCAN_u16IL_TimerTriTimeBKGLight
      data Val: category=VALUE, sw-calibration-access=READ-ONLY, type=uint16
    gCAN_u8IL_TimerActionModeBKGLight
      data Val: category=VALUE, sw-calibration-access=READ-ONLY, type=uint8
    gCAN_u8IL_TimerGradientTimeBKGLight
      data Val: category=VALUE, sw-calibration-access=READ-ONLY, type=uint8
    gDiag_bReBkgLightPowerShortCirErrorFlag
      data Val: category=VALUE, sw-calibration-access=READ-ONLY, type=boolean
    gDiag_bReBkgLightPowerOpenCirErrorFlag
      data Val: category=VALUE, sw-calibration-access=READ-ONLY, type=boolean
    gASI_bIL_CtrCmdTrunkLight_TimeOut
      data Val: category=VALUE, sw-calibration-access=READ-ONLY, type=boolean
